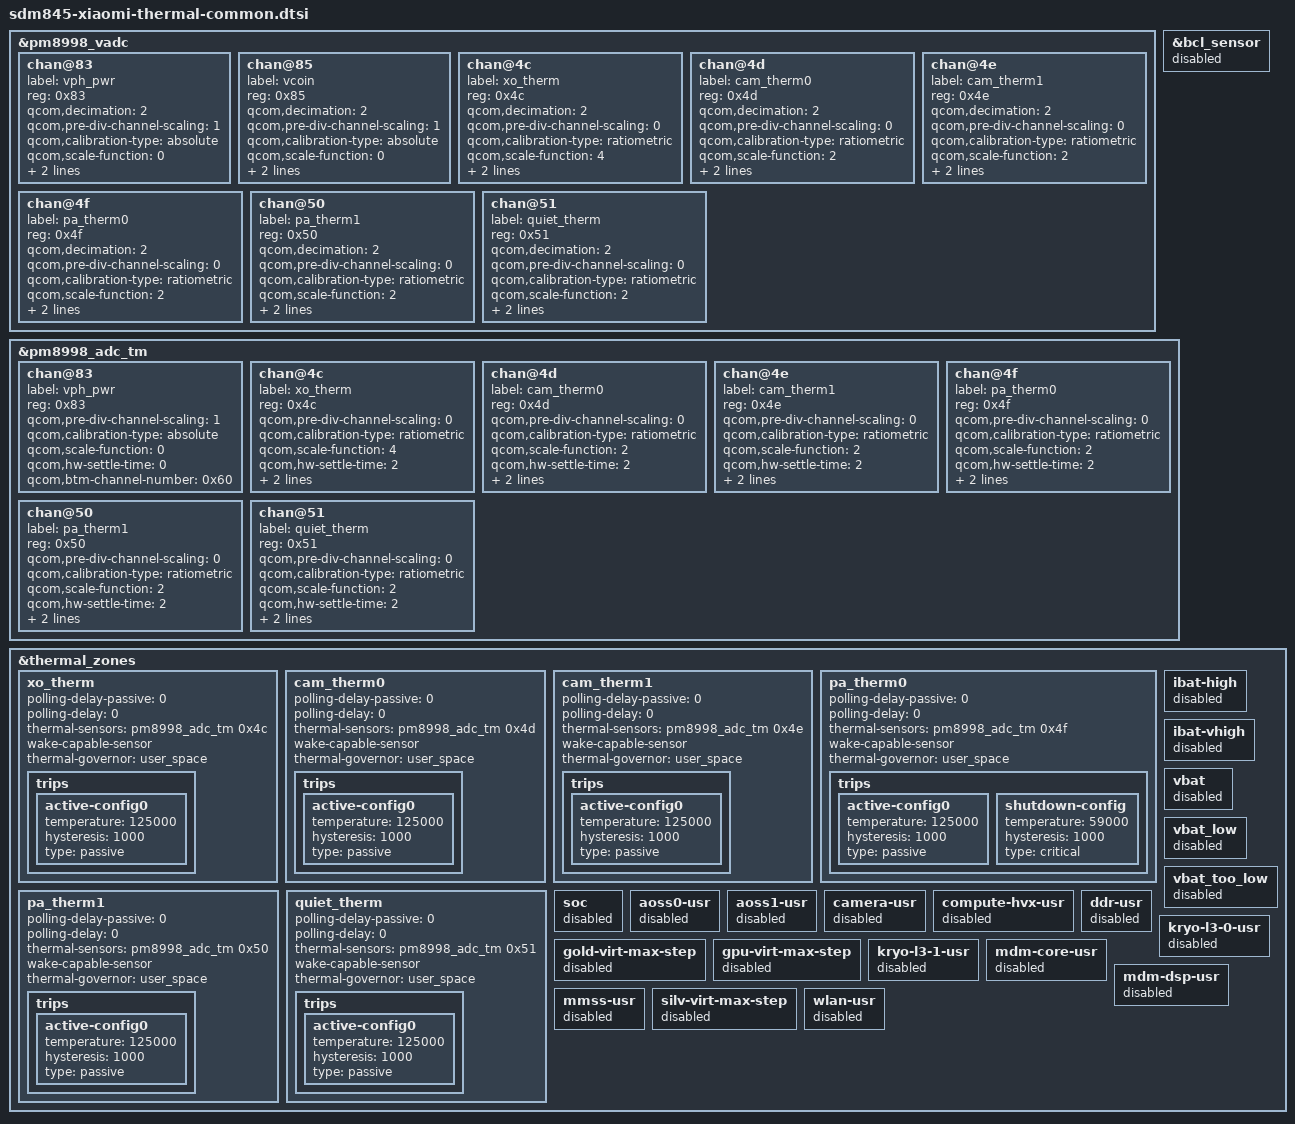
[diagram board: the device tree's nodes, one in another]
/* arch/arm64/boot/dts/qcom/sdm845-xiaomi-thermal-common.dtsi
 *
 * This program is free software; you can redistribute it and/or modify
 * it under the terms of the GNU General Public License version 2 and
 * only version 2 as published by the Free Software Foundation.
 *
 * This program is distributed in the hope that it will be useful,
 * but WITHOUT ANY WARRANTY; without even the implied warranty of
 * MERCHANTABILITY or FITNESS FOR A PARTICULAR PURPOSE.  See the
 * GNU General Public License for more details.
 */
 
/*
 * Copyright (C) 2019 Raphiel Rollerscaperers <raphielscape@outlook.com>
 *
 * This program is free software; you can redistribute it and/or modify
 * it under the terms of the GNU General Public License version 2, as
 * published by the Free Software Foundation.
 */


&pm8998_vadc {
	chan@83 {
		label = "vph_pwr";
		reg = <0x83>;
		qcom,decimation = <2>;
		qcom,pre-div-channel-scaling = <1>;
		qcom,calibration-type = "absolute";
		qcom,scale-function = <0>;
		qcom,hw-settle-time = <0>;
		qcom,fast-avg-setup = <0>;
	};

	chan@85 {
		label = "vcoin";
		reg = <0x85>;
		qcom,decimation = <2>;
		qcom,pre-div-channel-scaling = <1>;
		qcom,calibration-type = "absolute";
		qcom,scale-function = <0>;
		qcom,hw-settle-time = <0>;
		qcom,fast-avg-setup = <0>;
	};

	chan@4c {
		label = "xo_therm";
		reg = <0x4c>;
		qcom,decimation = <2>;
		qcom,pre-div-channel-scaling = <0>;
		qcom,calibration-type = "ratiometric";
		qcom,scale-function = <4>;
		qcom,hw-settle-time = <2>;
		qcom,fast-avg-setup = <0>;
	};

	chan@4d {
		label = "cam_therm0";
		reg = <0x4d>;
		qcom,decimation = <2>;
		qcom,pre-div-channel-scaling = <0>;
		qcom,calibration-type = "ratiometric";
		qcom,scale-function = <2>;
		qcom,hw-settle-time = <2>;
		qcom,fast-avg-setup = <0>;
	};

	chan@4e {
		label = "cam_therm1";
		reg = <0x4e>;
		qcom,decimation = <2>;
		qcom,pre-div-channel-scaling = <0>;
		qcom,calibration-type = "ratiometric";
		qcom,scale-function = <2>;
		qcom,hw-settle-time = <2>;
		qcom,fast-avg-setup = <0>;
	};

	chan@4f {
		label = "pa_therm0";
		reg = <0x4f>;
		qcom,decimation = <2>;
		qcom,pre-div-channel-scaling = <0>;
		qcom,calibration-type = "ratiometric";
		qcom,scale-function = <2>;
		qcom,hw-settle-time = <2>;
		qcom,fast-avg-setup = <0>;
	};

	chan@50 {
		label = "pa_therm1";
		reg = <0x50>;
		qcom,decimation = <2>;
		qcom,pre-div-channel-scaling = <0>;
		qcom,calibration-type = "ratiometric";
		qcom,scale-function = <2>;
		qcom,hw-settle-time = <2>;
		qcom,fast-avg-setup = <0>;
	};

	chan@51 {
		label = "quiet_therm";
		reg = <0x51>;
		qcom,decimation = <2>;
		qcom,pre-div-channel-scaling = <0>;
		qcom,calibration-type = "ratiometric";
		qcom,scale-function = <2>;
		qcom,hw-settle-time = <2>;
		qcom,fast-avg-setup = <0>;
	};
};

&bcl_sensor {
	status = "disabled";
};

&pm8998_adc_tm {
	chan@83 {
		label = "vph_pwr";
		reg = <0x83>;
		qcom,pre-div-channel-scaling = <1>;
		qcom,calibration-type = "absolute";
		qcom,scale-function = <0>;
		qcom,hw-settle-time = <0>;
		qcom,btm-channel-number = <0x60>;
	};

	chan@4c {
		label = "xo_therm";
		reg = <0x4c>;
		qcom,pre-div-channel-scaling = <0>;
		qcom,calibration-type = "ratiometric";
		qcom,scale-function = <4>;
		qcom,hw-settle-time = <2>;
		qcom,btm-channel-number = <0x68>;
		qcom,thermal-node;
	};

	chan@4d {
		label = "cam_therm0";
		reg = <0x4d>;
		qcom,pre-div-channel-scaling = <0>;
		qcom,calibration-type = "ratiometric";
		qcom,scale-function = <2>;
		qcom,hw-settle-time = <2>;
		qcom,btm-channel-number = <0x88>;
		qcom,thermal-node;
	};

	chan@4e {
		label = "cam_therm1";
		reg = <0x4e>;
		qcom,pre-div-channel-scaling = <0>;
		qcom,calibration-type = "ratiometric";
		qcom,scale-function = <2>;
		qcom,hw-settle-time = <2>;
		qcom,btm-channel-number = <0x70>;
		qcom,thermal-node;
	};

	chan@4f {
		label = "pa_therm0";
		reg = <0x4f>;
		qcom,pre-div-channel-scaling = <0>;
		qcom,calibration-type = "ratiometric";
		qcom,scale-function = <2>;
		qcom,hw-settle-time = <2>;
		qcom,btm-channel-number = <0x78>;
		qcom,thermal-node;
	};

	chan@50 {
		label = "pa_therm1";
		reg = <0x50>;
		qcom,pre-div-channel-scaling = <0>;
		qcom,calibration-type = "ratiometric";
		qcom,scale-function = <2>;
		qcom,hw-settle-time = <2>;
		qcom,btm-channel-number = <0x90>;
		qcom,thermal-node;
	};

	chan@51 {
		label = "quiet_therm";
		reg = <0x51>;
		qcom,pre-div-channel-scaling = <0>;
		qcom,calibration-type = "ratiometric";
		qcom,scale-function = <2>;
		qcom,hw-settle-time = <2>;
		qcom,btm-channel-number = <0x80>;
		qcom,thermal-node;
	};
};

&thermal_zones {
	xo_therm {
		polling-delay-passive = <0>;
		polling-delay = <0>;
		thermal-sensors = <&pm8998_adc_tm 0x4c>;
		wake-capable-sensor;
		thermal-governor = "user_space";

		trips {
			active-config0 {
				temperature = <125000>;
				hysteresis = <1000>;
				type = "passive";
			};
		};
	};

	cam_therm0 {
		polling-delay-passive = <0>;
		polling-delay = <0>;
		thermal-sensors = <&pm8998_adc_tm 0x4d>;
		wake-capable-sensor;
		thermal-governor = "user_space";

		trips {
			active-config0 {
				temperature = <125000>;
				hysteresis = <1000>;
				type = "passive";
			};
		};
	};

	cam_therm1 {
		polling-delay-passive = <0>;
		polling-delay = <0>;
		thermal-sensors = <&pm8998_adc_tm 0x4e>;
		wake-capable-sensor;
		thermal-governor = "user_space";

		trips {
			active-config0 {
				temperature = <125000>;
				hysteresis = <1000>;
				type = "passive";
			};
		};
	};

	pa_therm0 {
		polling-delay-passive = <0>;
		polling-delay = <0>;
		thermal-sensors = <&pm8998_adc_tm 0x4f>;
		wake-capable-sensor;
		thermal-governor = "user_space";

		trips {
			active-config0 {
				temperature = <125000>;
				hysteresis = <1000>;
				type = "passive";
			};
			shutdown-config {
				temperature = <59000>;
				hysteresis = <1000>;
				type = "critical";
			};
		};
	};

	pa_therm1 {
		polling-delay-passive = <0>;
		polling-delay = <0>;
		thermal-sensors = <&pm8998_adc_tm 0x50>;
		wake-capable-sensor;
		thermal-governor = "user_space";

		trips {
			active-config0 {
				temperature = <125000>;
				hysteresis = <1000>;
				type = "passive";
			};
		};
	};

	quiet_therm {
		polling-delay-passive = <0>;
		polling-delay = <0>;
		thermal-sensors = <&pm8998_adc_tm 0x51>;
		wake-capable-sensor;
		thermal-governor = "user_space";

		trips {
			active-config0 {
				temperature = <125000>;
				hysteresis = <1000>;
				type = "passive";
			};
		};
	};

	ibat-high {
		status = "disabled";
	};

	ibat-vhigh {
		status = "disabled";
	};

	vbat {
		status = "disabled";
	};

	vbat_low {
		status = "disabled";
	};

	vbat_too_low {
		status = "disabled";
	};

	soc {
		status = "disabled";
	};

	aoss0-usr {
		status = "disabled";
	};

	aoss1-usr {
		status = "disabled";
	};

	camera-usr {
		status = "disabled";
	};

	compute-hvx-usr {
		status = "disabled";
	};

	ddr-usr {
		status = "disabled";
	};

	gold-virt-max-step {
		status = "disabled";
	};

	gpu-virt-max-step {
		status = "disabled";
	};

	kryo-l3-0-usr {
		status = "disabled";
	};

	kryo-l3-1-usr {
		status = "disabled";
	};

	mdm-core-usr {
		status = "disabled";
	};

	mdm-dsp-usr {
		status = "disabled";
	};

	mmss-usr {
		status = "disabled";
	};

	silv-virt-max-step {
		status = "disabled";
	};

	wlan-usr {
		status = "disabled";
	};
};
